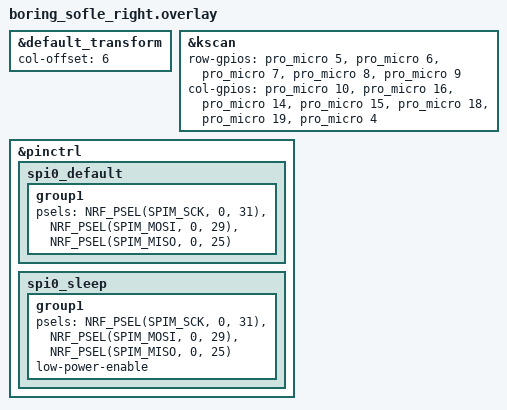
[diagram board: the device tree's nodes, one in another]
// This file was generated from a template. Edit it to match your keyboard.
// See https://zmk.dev/docs/development/hardware-integration/new-shield for more
// instructions.

#include "boring_sofle.dtsi"

&default_transform {
    // Set this to the number of columns on the left side.
    col-offset = <6>;
};

&kscan {
    row-gpios
        = <&pro_micro 5 (GPIO_ACTIVE_HIGH | GPIO_PULL_DOWN)>
        , <&pro_micro 6 (GPIO_ACTIVE_HIGH | GPIO_PULL_DOWN)>
        , <&pro_micro 7 (GPIO_ACTIVE_HIGH | GPIO_PULL_DOWN)>
        , <&pro_micro 8 (GPIO_ACTIVE_HIGH | GPIO_PULL_DOWN)>
        , <&pro_micro 9 (GPIO_ACTIVE_HIGH | GPIO_PULL_DOWN)>
        ;

    col-gpios
        = <&pro_micro 10 GPIO_ACTIVE_HIGH>
        , <&pro_micro 16 GPIO_ACTIVE_HIGH>
        , <&pro_micro 14 GPIO_ACTIVE_HIGH>
        , <&pro_micro 15 GPIO_ACTIVE_HIGH>
        , <&pro_micro 18 GPIO_ACTIVE_HIGH>
        , <&pro_micro 19 GPIO_ACTIVE_HIGH>
        , <&pro_micro 4 GPIO_ACTIVE_HIGH> // 5 way nav switch
        ;
};

// The MOSI and SLC pins don't have jumpers and are reversed between halves
&pinctrl {
    spi0_default: spi0_default {
        group1 {
            psels = <NRF_PSEL(SPIM_SCK, 0, 31)>,
                <NRF_PSEL(SPIM_MOSI, 0, 29)>,
                <NRF_PSEL(SPIM_MISO, 0, 25)>;
        };
    };
    spi0_sleep: spi0_sleep {
        group1 {
            psels = <NRF_PSEL(SPIM_SCK, 0, 31)>,
                <NRF_PSEL(SPIM_MOSI, 0, 29)>,
                <NRF_PSEL(SPIM_MISO, 0, 25)>;
            low-power-enable;
        };
    };
};
